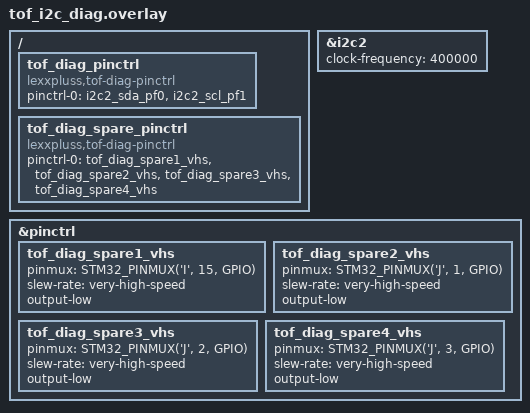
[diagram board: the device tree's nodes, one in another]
/*
 * Copyright (c) 2026, LexxPluss Inc.
 * All rights reserved.
 *
 * Diagnostic overlay for the firmware_tof_i2c_diag build only.
 *
 * - Sets i2c2 to 400 kHz explicitly: the binding default is 100 kHz, at
 *   which no ToF schedule closes (see docs and the bandwidth analysis).
 *   The `tof_diag speed` shell command can still move it at runtime.
 * - Declares /tof_diag_pinctrl so the shell can hand PF0/PF1 back to the
 *   I2C2 alternate function after a bit-bang session, via the pinctrl API
 *   instead of raw register writes.
 * - Declares /tof_diag_spare_pinctrl: which of SparePinGPIO1..4 ends up as
 *   LPn/CLK is a bench decision (`lpn use`), so all four are raised to
 *   very-high-speed rather than picking one ahead of time.
 *
 * `output-low` is required on every one of the four states below, not just
 * cosmetic: the STM32 pinctrl macro (Z_PINCTRL_STM32_PINCFG_INIT) only sets
 * the MODER bits to GPIO_OUTPUT when `output-low`/`output-high` is present;
 * without it MODER stays 0 (INPUT). Applying this state after
 * gpio_pin_configure_dt() has already set OUTPUT mode would silently revert
 * the pin to a floating input, and gpio_pin_set_dt()/clk_pulse() would then
 * write ODR bits that never reach the physical pin.
 */

#include <zephyr/dt-bindings/pinctrl/stm32-pinctrl.h>

&i2c2 {
    clock-frequency = <400000>;
};

&pinctrl {
    tof_diag_spare1_vhs: tof_diag_spare1_vhs {
        pinmux = <STM32_PINMUX('I', 15, GPIO)>;
        slew-rate = "very-high-speed";
        output-low;
    };
    tof_diag_spare2_vhs: tof_diag_spare2_vhs {
        pinmux = <STM32_PINMUX('J', 1, GPIO)>;
        slew-rate = "very-high-speed";
        output-low;
    };
    tof_diag_spare3_vhs: tof_diag_spare3_vhs {
        pinmux = <STM32_PINMUX('J', 2, GPIO)>;
        slew-rate = "very-high-speed";
        output-low;
    };
    tof_diag_spare4_vhs: tof_diag_spare4_vhs {
        pinmux = <STM32_PINMUX('J', 3, GPIO)>;
        slew-rate = "very-high-speed";
        output-low;
    };
};

/ {
    tof_diag_pinctrl: tof_diag_pinctrl {
        compatible = "lexxpluss,tof-diag-pinctrl";
        pinctrl-0 = <&i2c2_sda_pf0 &i2c2_scl_pf1>;
        pinctrl-names = "default";
        status = "okay";
    };

    tof_diag_spare_pinctrl: tof_diag_spare_pinctrl {
        compatible = "lexxpluss,tof-diag-pinctrl";
        pinctrl-0 = <&tof_diag_spare1_vhs &tof_diag_spare2_vhs
                     &tof_diag_spare3_vhs &tof_diag_spare4_vhs>;
        pinctrl-names = "default";
        status = "okay";
    };
};
